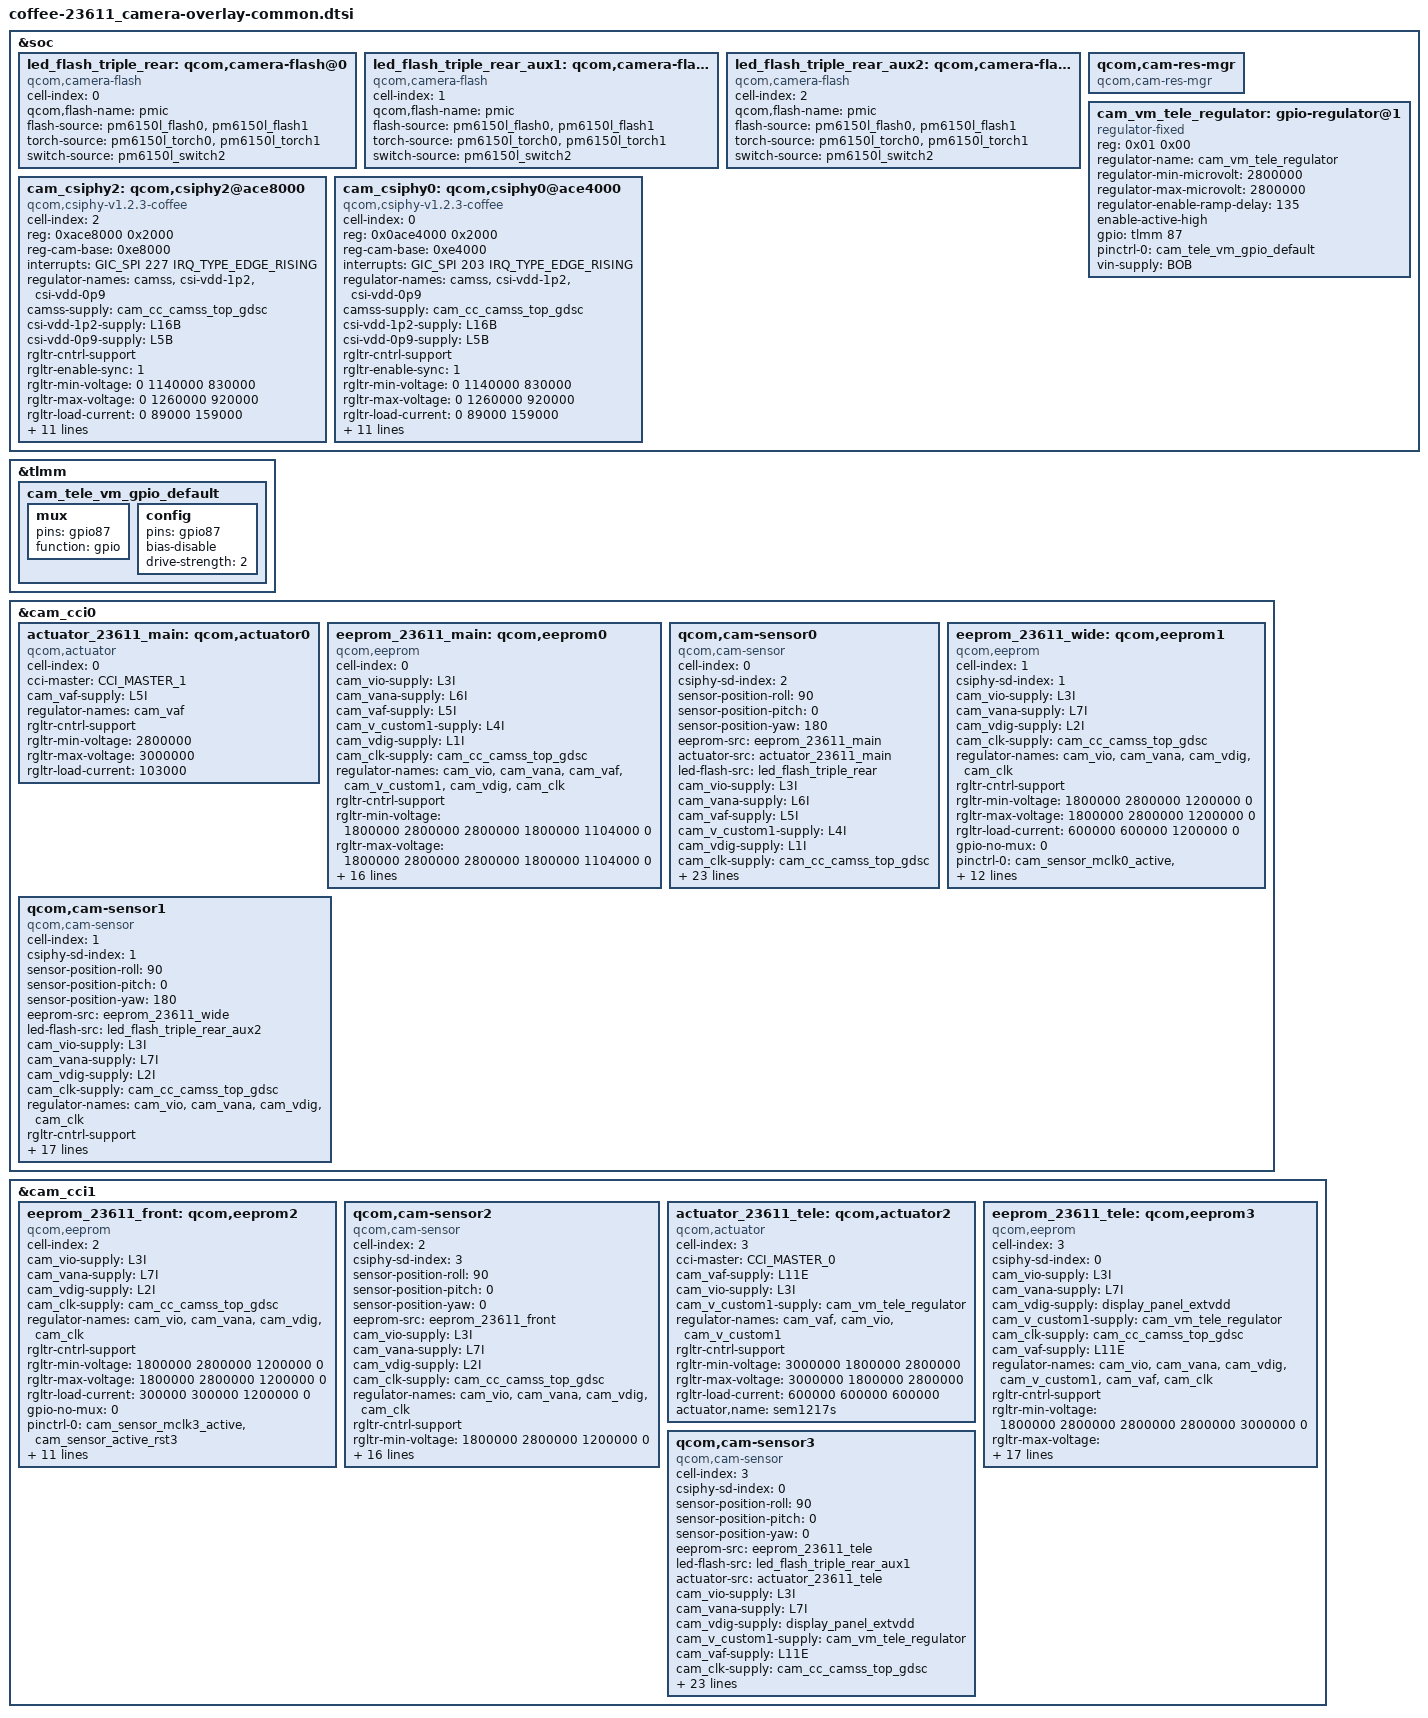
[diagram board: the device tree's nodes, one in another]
#include <dt-bindings/clock/qcom,camcc-parrot.h>
#include <dt-bindings/msm-camera.h>

&soc {
	led_flash_triple_rear: qcom,camera-flash@0 {
		cell-index = <0>;
		compatible = "qcom,camera-flash";
		qcom,flash-name = "pmic";
		flash-source = <&pm6150l_flash0 &pm6150l_flash1>;
		torch-source = <&pm6150l_torch0 &pm6150l_torch1>;
		switch-source = <&pm6150l_switch2>;
		status = "ok";
	};

	led_flash_triple_rear_aux1: qcom,camera-flash@1 {
		cell-index = <1>;
		compatible = "qcom,camera-flash";
		qcom,flash-name = "pmic";
		flash-source = <&pm6150l_flash0 &pm6150l_flash1>;
		torch-source = <&pm6150l_torch0 &pm6150l_torch1>;
		switch-source = <&pm6150l_switch2>;
		status = "ok";
	};

	led_flash_triple_rear_aux2: qcom,camera-flash@2 {
		cell-index = <2>;
		compatible = "qcom,camera-flash";
		qcom,flash-name = "pmic";
		flash-source = <&pm6150l_flash0 &pm6150l_flash1>;
		torch-source = <&pm6150l_torch0 &pm6150l_torch1>;
		switch-source = <&pm6150l_switch2>;
		status = "ok";
	};

	qcom,cam-res-mgr {
		compatible = "qcom,cam-res-mgr";
		status = "ok";
	};

	cam_vm_tele_regulator: gpio-regulator@1 {
		compatible = "regulator-fixed";
		reg = <0x01 0x00>;
		regulator-name = "cam_vm_tele_regulator";
		regulator-min-microvolt = <2800000>;
		regulator-max-microvolt = <2800000>;
		regulator-enable-ramp-delay = <135>;
		enable-active-high;
		gpio = <&tlmm 87 0>;
		pinctrl-names = "default";
		pinctrl-0 = <&cam_tele_vm_gpio_default>;
		vin-supply = <&BOB>;
	};

      cam_csiphy2: qcom,csiphy2@ace8000 {
		cell-index = <2>;
		compatible = "qcom,csiphy-v1.2.3-coffee", "qcom,csiphy";
		reg = <0xace8000 0x2000>;
		reg-names = "csiphy";
		reg-cam-base = <0xe8000>;
		interrupt-names = "CSIPHY2";
		interrupts = <GIC_SPI 227 IRQ_TYPE_EDGE_RISING>;
		regulator-names = "camss", "csi-vdd-1p2", "csi-vdd-0p9";
		camss-supply = <&cam_cc_camss_top_gdsc>;
		csi-vdd-1p2-supply = <&L16B>;
		csi-vdd-0p9-supply = <&L5B>;
		rgltr-cntrl-support;
		rgltr-enable-sync = <1>;
		rgltr-min-voltage = <0 1140000 830000>;
		rgltr-max-voltage = <0 1260000 920000>;
		rgltr-load-current = <0 89000 159000>;
		shared-clks = <1 0 0 0>;
		clock-names = "cphy_rx_clk_src",
			"csiphy2_clk",
			"csi2phytimer_clk_src",
			"csi2phytimer_clk";
		clocks = <&camcc CAM_CC_CPHY_RX_CLK_SRC>,
			<&camcc CAM_CC_CSIPHY2_CLK>,
			<&camcc CAM_CC_CSI2PHYTIMER_CLK_SRC>,
			<&camcc CAM_CC_CSI2PHYTIMER_CLK>;
		src-clock-name = "csi2phytimer_clk_src";
		clock-cntl-level = "lowsvs", "svs", "svs_l1", "nominal";
		clock-rates =
			<300000000 0 300000000 0>,
			<400000000 0 300000000 0>,
			<400000000 0 300000000 0>,
			<400000000 0 300000000 0>;
		status = "ok";
	};

	cam_csiphy0: qcom,csiphy0@ace4000 {
		cell-index = <0>;
		compatible = "qcom,csiphy-v1.2.3-coffee", "qcom,csiphy";
		reg = < 0x0ace4000 0x2000>;
		reg-names = "csiphy";
		reg-cam-base = <0xe4000>;
		interrupt-names = "CSIPHY0";
		interrupts = <GIC_SPI 203 IRQ_TYPE_EDGE_RISING>;
		regulator-names = "camss", "csi-vdd-1p2", "csi-vdd-0p9";
		camss-supply = <&cam_cc_camss_top_gdsc>;
		csi-vdd-1p2-supply = <&L16B>;
		csi-vdd-0p9-supply = <&L5B>;
		rgltr-cntrl-support;
		rgltr-enable-sync = <1>;
		rgltr-min-voltage = <0 1140000 830000>;
		rgltr-max-voltage = <0 1260000 920000>;
		rgltr-load-current = <0 89000 159000>;
		shared-clks = <1 0 0 0>;
		clock-names = "cphy_rx_clk_src",
			"csiphy0_clk",
			"csi0phytimer_clk_src",
			"csi0phytimer_clk";
		clocks = <&camcc CAM_CC_CPHY_RX_CLK_SRC>,
			<&camcc CAM_CC_CSIPHY0_CLK>,
			<&camcc CAM_CC_CSI0PHYTIMER_CLK_SRC>,
			<&camcc CAM_CC_CSI0PHYTIMER_CLK>;
		src-clock-name = "csi0phytimer_clk_src";
		clock-cntl-level = "lowsvs", "svs", "svs_l1", "nominal";
		clock-rates =
			<300000000 0 300000000 0>,
			<400000000 0 300000000 0>,
			<400000000 0 300000000 0>,
			<400000000 0 300000000 0>;
		status = "ok";
	};

};

&tlmm {
		cam_tele_vm_gpio_default: cam_tele_vm_gpio_default {
			/*  VIO LDO */
			mux {
				pins = "gpio87";
				function = "gpio";
			};
			config {
				pins = "gpio87";
				bias-disable; /* No PULL */
				drive-strength = <2>; /* 2 MA */
			};
		};
};

&cam_cci0 {
    actuator_23611_main: qcom,actuator0 {
		cell-index = <0>;
		compatible = "qcom,actuator";
		cci-master = <CCI_MASTER_1>;
		cam_vaf-supply = <&L5I>;
		regulator-names = "cam_vaf";
		rgltr-cntrl-support;
		rgltr-min-voltage = <2800000>;
		rgltr-max-voltage = <3000000>;
		rgltr-load-current = <103000>;
	};
	eeprom_23611_main: qcom,eeprom0 {
		cell-index = <0>;
		compatible = "qcom,eeprom";
		cam_vio-supply = <&L3I>;
		cam_vana-supply = <&L6I>;
		cam_vaf-supply = <&L5I>;
                cam_v_custom1-supply = <&L4I>;  //senna
		cam_vdig-supply = <&L1I>;
		cam_clk-supply = <&cam_cc_camss_top_gdsc>;
		regulator-names = "cam_vio", "cam_vana", "cam_vaf","cam_v_custom1",
			"cam_vdig", "cam_clk";
		rgltr-cntrl-support;
		rgltr-min-voltage = <1800000 2800000 2800000 1800000 1104000 0>;
		rgltr-max-voltage = <1800000 2800000 2800000 1800000 1104000 0>;
		rgltr-load-current = <300000 300000  300000  300000  1200000 0>;
		gpio-no-mux = <0>;
		pinctrl-names = "cam_default", "cam_suspend";
		pinctrl-0 = <&cam_sensor_mclk1_active
				 &cam_sensor_active_rst1>;
		pinctrl-1 = <&cam_sensor_mclk1_suspend
				 &cam_sensor_suspend_rst1>;
		gpios = <&tlmm 40 0>,
			<&tlmm 45 0>;
		gpio-reset = <1>;
		gpio-req-tbl-num = <0 1>;
		gpio-req-tbl-flags = <1 0>;
		gpio-req-tbl-label = "CAMIF_MCLK1",
					"CAM_RESET1";
		cci-master = <CCI_MASTER_1>;
		clocks = <&camcc CAM_CC_MCLK1_CLK>;
		clock-names = "cam_clk";
		clock-cntl-level = "nominal";
		clock-rates = <24000000>;
		status = "ok";

	};

    //imx890
    qcom,cam-sensor0 {
		cell-index = <0>;
		compatible = "qcom,cam-sensor";
		csiphy-sd-index = <2>;
		sensor-position-roll = <90>;
		sensor-position-pitch = <0>;
		sensor-position-yaw = <180>;
		eeprom-src = <&eeprom_23611_main>;
		actuator-src = <&actuator_23611_main>;
		//ois-src = <&ois_23611_main>;
		led-flash-src = <&led_flash_triple_rear>;
		cam_vio-supply = <&L3I>;
		cam_vana-supply = <&L6I>;
		cam_vaf-supply = <&L5I>;
                cam_v_custom1-supply = <&L4I>;  //senna
		cam_vdig-supply = <&L1I>;
		cam_clk-supply = <&cam_cc_camss_top_gdsc>;
		regulator-names = "cam_vio", "cam_vana", "cam_vaf","cam_v_custom1",
			"cam_vdig", "cam_clk";
		rgltr-cntrl-support;
		rgltr-min-voltage = <1800000 2800000 2800000 1800000 1104000 0>;
		rgltr-max-voltage = <1800000 2800000 2800000 1800000 1104000 0>;
		rgltr-load-current = <300000 300000  300000  300000  1200000 0>;

		gpio-no-mux = <0>;
		pinctrl-names = "cam_default", "cam_suspend";
		pinctrl-0 = <&cam_sensor_mclk1_active
				 &cam_sensor_active_rst1>;
		pinctrl-1 = <&cam_sensor_mclk1_suspend
				 &cam_sensor_suspend_rst1>;
		gpios = <&tlmm 40 0>,
			<&tlmm 45 0>;
		gpio-reset = <1>;
		gpio-req-tbl-num = <0 1>;
		gpio-req-tbl-flags = <1 0>;
		gpio-req-tbl-label = "CAMIF_MCLK1",
					"CAM_RESET1";
		cci-master = <CCI_MASTER_1>;
		clocks = <&camcc CAM_CC_MCLK1_CLK>;
		clock-names = "cam_clk";
		clock-cntl-level = "nominal";
		clock-rates = <24000000>;
		status = "ok";
		//is-read-eeprom = <2>;
		//is_power_up_advance = <2>;
		//enable_qsc_write_in_advance = <1>;
		//qsc_reg_addr = <0x1E30>;
		//eeprom_slave_addr = <0xA0>;
		//qsc_data_size = <3072>;
		//write_qsc_addr = <0xC800>;
	};

    //hi846
   eeprom_23611_wide: qcom,eeprom1 {
		cell-index = <1>;
		compatible = "qcom,eeprom";
		csiphy-sd-index = <1>;
		cam_vio-supply = <&L3I>;
		cam_vana-supply = <&L7I>;
		cam_vdig-supply = <&L2I>;
		cam_clk-supply = <&cam_cc_camss_top_gdsc>;
		regulator-names = "cam_vio", "cam_vana", "cam_vdig","cam_clk";
		rgltr-cntrl-support;
		rgltr-min-voltage = <1800000 2800000 1200000  0 >;
		rgltr-max-voltage = <1800000 2800000 1200000  0 >;
		rgltr-load-current = <600000 600000 1200000  0 >;
		gpio-no-mux = <0>;
		pinctrl-names = "cam_default", "cam_suspend";
		pinctrl-0 = <&cam_sensor_mclk0_active
				 &cam_sensor_active_rst0>;
		pinctrl-1 = <&cam_sensor_mclk0_suspend
				 &cam_sensor_suspend_rst0>;
		gpios = <&tlmm 39 0>,
			<&tlmm 44 0>;
		gpio-reset = <1>;
		gpio-req-tbl-num = <0 1>;
		gpio-req-tbl-flags = <1 0>;
		gpio-req-tbl-label = "CAMIF_MCLK0",
					"CAM_RESET0";
		cci-master = <CCI_MASTER_0>;
		clocks = <&camcc CAM_CC_MCLK0_CLK>;
		clock-names = "cam_clk";
		clock-cntl-level = "nominal";
		clock-rates = <24000000>;
		status = "ok";
	};
    qcom,cam-sensor1 {
		cell-index = <1>;
		compatible = "qcom,cam-sensor";
		csiphy-sd-index = <1>;
		sensor-position-roll = <90>;
		sensor-position-pitch = <0>;
		sensor-position-yaw = <180>;
		eeprom-src = <&eeprom_23611_wide>;
		led-flash-src = <&led_flash_triple_rear_aux2>;
		cam_vio-supply = <&L3I>;
		cam_vana-supply = <&L7I>;
		cam_vdig-supply = <&L2I>;
		cam_clk-supply = <&cam_cc_camss_top_gdsc>;
		regulator-names = "cam_vio", "cam_vana", "cam_vdig","cam_clk";
		rgltr-cntrl-support;
		rgltr-min-voltage = <1800000 2800000 1200000  0 >;
		rgltr-max-voltage = <1800000 2800000 1200000  0 >;
		rgltr-load-current = <600000 600000 1200000  0 >;
		gpio-no-mux = <0>;
		pinctrl-names = "cam_default", "cam_suspend";
		pinctrl-0 = <&cam_sensor_mclk0_active
				 &cam_sensor_active_rst0>;
		pinctrl-1 = <&cam_sensor_mclk0_suspend
				 &cam_sensor_suspend_rst0>;
		gpios = <&tlmm 39 0>,
			<&tlmm 44 0>;
		gpio-reset = <1>;
		gpio-req-tbl-num = <0 1>;
		gpio-req-tbl-flags = <1 0>;
		gpio-req-tbl-label = "CAMIF_MCLK0",
					"CAM_RESET0";
		cci-master = <CCI_MASTER_0>;
		clocks = <&camcc CAM_CC_MCLK0_CLK>;
		clock-names = "cam_clk";
		clock-cntl-level = "nominal";
		clock-rates = <24000000>;
		status = "ok";
	};
};

&cam_cci1 {
eeprom_23611_front: qcom,eeprom2 {
		cell-index = <2>;
		compatible = "qcom,eeprom";
		cam_vio-supply = <&L3I>;
		cam_vana-supply = <&L7I>;
		cam_vdig-supply = <&L2I>;
		cam_clk-supply = <&cam_cc_camss_top_gdsc>;
		regulator-names = "cam_vio", "cam_vana", "cam_vdig","cam_clk";
		rgltr-cntrl-support;
		rgltr-min-voltage = <1800000 2800000 1200000  0>;
		rgltr-max-voltage = <1800000 2800000 1200000  0>;
		rgltr-load-current = <300000 300000 1200000  0>;
		gpio-no-mux = <0>;
		pinctrl-names = "cam_default", "cam_suspend";
		pinctrl-0 = <&cam_sensor_mclk3_active
				&cam_sensor_active_rst3>;
		pinctrl-1 = <&cam_sensor_mclk3_suspend
				&cam_sensor_suspend_rst3>;
		gpios = <&tlmm 42 0>,
			<&tlmm 47 0>;
		gpio-reset = <1>;
		gpio-req-tbl-num = <0 1>;
		gpio-req-tbl-flags = <1 0>;
		gpio-req-tbl-label = "CAMIF_MCLK3",
					"CAM_RESET3";
		cci-master = <CCI_MASTER_1>;
		clocks = <&camcc CAM_CC_MCLK3_CLK>;
		clock-names = "cam_clk";
		clock-cntl-level = "nominal";
		clock-rates = <24000000>;
		status = "ok";
	};

    //imx615
    qcom,cam-sensor2 {
		cell-index = <2>;
		compatible = "qcom,cam-sensor";
		csiphy-sd-index = <3>;
		sensor-position-roll = <90>;
		sensor-position-pitch = <0>;
		sensor-position-yaw = <0>;
		eeprom-src = <&eeprom_23611_front>;
		//led-flash-src = <&led_flash_rear_tele>;
		cam_vio-supply = <&L3I>;
		cam_vana-supply = <&L7I>;
		cam_vdig-supply = <&L2I>; //gpio131
		cam_clk-supply = <&cam_cc_camss_top_gdsc>;
		regulator-names = "cam_vio", "cam_vana", "cam_vdig","cam_clk";
		rgltr-cntrl-support;
		rgltr-min-voltage = <1800000 2800000 1200000  0 >;
		rgltr-max-voltage = <1800000 2800000 1200000  0 >;
		rgltr-load-current = <300000 300000 1200000  0>;
		gpio-no-mux = <0>;
		pinctrl-names = "cam_default", "cam_suspend";
		pinctrl-0 = <&cam_sensor_mclk3_active
				 &cam_sensor_active_rst3>;
		pinctrl-1 = <&cam_sensor_mclk3_suspend
				 &cam_sensor_suspend_rst3>;
		gpios = <&tlmm 42 0>,
			<&tlmm 47 0>;
		gpio-reset = <1>;
		gpio-req-tbl-num = <0 1>;
		gpio-req-tbl-flags = <1 0>;
		gpio-req-tbl-label = "CAMIF_MCLK3",
					"CAM_RESET3";
		cci-master = <CCI_MASTER_1>;
		clocks = <&camcc CAM_CC_MCLK3_CLK>;
		clock-names = "cam_clk";
		clock-cntl-level = "nominal";
		clock-rates = <24000000>;
		status = "ok";
	};

	actuator_23611_tele: qcom,actuator2 {
		cell-index = <3>;
		compatible = "qcom,actuator";
		cci-master = <CCI_MASTER_0>;
		cam_vaf-supply = <&L11E>;
		cam_vio-supply = <&L3I>;
		cam_v_custom1-supply = <&cam_vm_tele_regulator>;
		regulator-names = "cam_vaf", "cam_vio", "cam_v_custom1";
		rgltr-cntrl-support;
		rgltr-min-voltage = <3000000 1800000 2800000>;
		rgltr-max-voltage = <3000000 1800000 2800000>;
		rgltr-load-current = <600000 600000 600000>;
		actuator,name = "sem1217s";
		status = "ok";
	};

	eeprom_23611_tele: qcom,eeprom3 {
		cell-index = <3>;
		compatible = "qcom,eeprom";
		csiphy-sd-index = <0>;
		cam_vio-supply = <&L3I>;
		cam_vana-supply = <&L7I>;
		cam_vdig-supply = <&display_panel_extvdd>;
		cam_v_custom1-supply = <&cam_vm_tele_regulator>; //sem1217s power on need ois af eeprom all supply gpio 87
		cam_clk-supply = <&cam_cc_camss_top_gdsc>;
		cam_vaf-supply = <&L11E>;
		regulator-names = "cam_vio", "cam_vana", "cam_vdig","cam_v_custom1","cam_vaf","cam_clk";
		rgltr-cntrl-support;
		rgltr-min-voltage = <1800000 2800000 2800000  2800000 3000000 0>;
		rgltr-max-voltage = <1800000 2800000 2800000  2800000 3000000 0>;
		rgltr-load-current = <300000 300000 600000  2800000 600000 0>;
		gpio-no-mux = <0>;
		pinctrl-names = "cam_default", "cam_suspend";
		pinctrl-0 = <&cam_sensor_mclk2_active
				 &cam_sensor_active_rst2>;
		pinctrl-1 = <&cam_sensor_mclk2_suspend
				 &cam_sensor_suspend_rst2>;
		gpios = <&tlmm 41 0>,
			<&tlmm 46 0>;
		gpio-reset = <1>;
		gpio-req-tbl-num = <0 1>;
		gpio-req-tbl-flags = <1 0>;
		gpio-req-tbl-label = "CAMIF_MCLK2",
					"CAM_RESET2";
		cci-master = <CCI_MASTER_0>;
		clocks = <&camcc CAM_CC_MCLK2_CLK>;
		clock-names = "cam_clk";
		clock-cntl-level = "nominal";
		clock-rates = <24000000>;
		status = "ok";
	};
	//OV64B
	qcom,cam-sensor3 {
		cell-index = <3>;
		compatible = "qcom,cam-sensor";
		csiphy-sd-index = <0>;
		sensor-position-roll = <90>;
		sensor-position-pitch = <0>;
		sensor-position-yaw = <0>;
		eeprom-src = <&eeprom_23611_tele>;
		led-flash-src = <&led_flash_triple_rear_aux1>;
		actuator-src = <&actuator_23611_tele>;
		//ois-src = <&ois_23611_tele>;
		cam_vio-supply = <&L3I>;
		cam_vana-supply = <&L7I>;
		cam_vdig-supply = <&display_panel_extvdd>; //gpio131  VREG_S8B_1P256
		cam_v_custom1-supply = <&cam_vm_tele_regulator>; //sem1217s power on need ois af eeprom all supply gpio 87
		cam_vaf-supply = <&L11E>;   //VREG_L11
		cam_clk-supply = <&cam_cc_camss_top_gdsc>;
		regulator-names = "cam_vio", "cam_vana", "cam_vdig","cam_v_custom1","cam_vaf","cam_clk";
		rgltr-cntrl-support;
		rgltr-min-voltage = <1800000 2800000 2800000 2800000 3000000 0>;
		rgltr-max-voltage = <1800000 2800000 2800000 2800000 3000000 0>;
		rgltr-load-current = <300000 300000 600000 2800000 600000 0>;
		gpio-no-mux = <0>;
		pinctrl-names = "cam_default", "cam_suspend";
		pinctrl-0 = <&cam_sensor_mclk2_active
				 &cam_sensor_active_rst2>;
		pinctrl-1 = <&cam_sensor_mclk2_suspend
				 &cam_sensor_suspend_rst2>;
		gpios = <&tlmm 41 0>,
			<&tlmm 46 0>;
		gpio-reset = <1>;
		gpio-req-tbl-num = <0 1>;
		gpio-req-tbl-flags = <1 0>;
		gpio-req-tbl-label = "CAMIF_MCLK2",
                             "CAM_RESET2";
		cci-master = <CCI_MASTER_0>;
		clocks = <&camcc CAM_CC_MCLK2_CLK>;
		clock-names = "cam_clk";
		clock-cntl-level = "nominal";
		clock-rates = <24000000>;
		status = "ok";
	};
};
